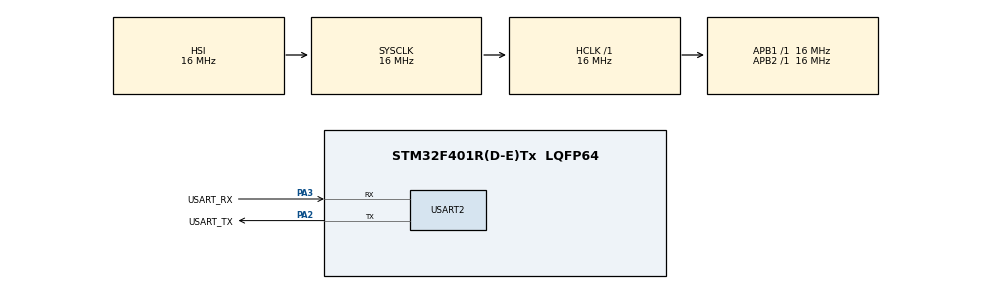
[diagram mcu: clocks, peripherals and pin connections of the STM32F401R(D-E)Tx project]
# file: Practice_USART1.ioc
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Mcu.Family=STM32F4
Mcu.Name=STM32F401R(D-E)Tx
Mcu.Package=LQFP64
NVIC.PriorityGroup=NVIC_PRIORITYGROUP_4
NVIC.USART2_IRQn=true\:1\:0\:true\:false\:true\:true\:true
PA2.GPIO_Label=USART_TX
PA2.Mode=Asynchronous
PA2.Signal=USART2_TX
PA3.GPIO_Label=USART_RX
PA3.Mode=Asynchronous
PA3.Signal=USART2_RX
ProjectManager.HeapSize=0x200
ProjectManager.StackSize=0x400
ProjectManager.TargetToolchain=TrueSTUDIO
RCC.AHBFreq_Value=16000000
RCC.APB1Freq_Value=16000000
RCC.APB2Freq_Value=16000000
RCC.CortexFreq_Value=16000000
RCC.HSE_VALUE=25000000
RCC.HSI_VALUE=16000000
RCC.LSE_VALUE=32768
RCC.SYSCLKFreq_VALUE=16000000
RCC.VCOOutputFreq_Value=192000000
USART2.VirtualMode=VM_ASYNC
board=custom

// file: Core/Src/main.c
/* USER CODE BEGIN Header */
/**
  ******************************************************************************
  * @file           : main.c
  * @brief          : Main program body
  ******************************************************************************
  * @attention
  *
  * <h2><center>&copy; Copyright (c) 2022 STMicroelectronics.
  * All rights reserved.</center></h2>
  *
  * This software component is licensed by ST under BSD 3-Clause license,
  * the "License"; You may not use this file except in compliance with the
  * License. You may obtain a copy of the License at:
  *                        opensource.org/licenses/BSD-3-Clause
  *
  ******************************************************************************
  */
/* USER CODE END Header */
#include "main.h"

/* USER CODE BEGIN Includes */
//ヘッダファイルのインクルード
#include <string.h>
/* USER CODE END Includes */

UART_HandleTypeDef huart2;

void SystemClock_Config(void);
static void MX_GPIO_Init(void);
static void MX_USART2_UART_Init(void);

/* USER CODE BEGIN 0 */
//uart_status変数の作成
__IO uint8_t uart_status;
//送受信格納用変数(8byte)
uint8_t uartbuff[8];
/* USER CODE END 0 */

int main(void)
{

  /* MCU Configuration--------------------------------------------------------*/

  /* Reset of all peripherals, Initializes the Flash interface and the Systick. */
  HAL_Init();

  /* Configure the system clock */
  SystemClock_Config();

  /* Initialize all configured peripherals */
  MX_GPIO_Init();
  MX_USART2_UART_Init();

  /* Infinite loop */
  while (1)
  {

    /* USER CODE BEGIN 3 */
	  //uart_status変数の初期化
	  uart_status = 0;
	  //送受信バッファのクリア
	  memset(uartbuff,0x00,sizeof(uartbuff));

	  //HAL_UART_Receive_ITはUART受信割込みITを開始するための、関数
	  /*第一引数：使用するUARTハンドラ
　　　 　第二引数：受信するためのバッファ
　　　　 第三引数：受信するバイト数*/
	  if(HAL_UART_Receive_IT(&huart2,uartbuff,1)== HAL_OK)
	  {
		  while(uart_status != 3)
		  {
			  switch(uart_status){
			  case 0:break; /*receive complete wait*/
			  case 1:
				  uart_status = 2;
				  /*UART送信開始用関数*/
				  /*第一引数：送信に使用するUARTハンドラ
　　　　　　　　　　　　 第二引数：送信するためのバッファ
　　　　　　　　　　　　 第三引数：送信バイト数*/
				  HAL_UART_Transmit_IT(&huart2,uartbuff,strlen((char const*)uartbuff));
				  break;
			  case 2:break;/*transmit complete wait*/
			  case 3:break;/*end*/
			  }/*end of switch*/
		  }/*end of while*/
	  }/*end of if*/
  }
  /* USER CODE END 3 */
}

void SystemClock_Config(void)
{
  RCC_OscInitTypeDef RCC_OscInitStruct = {0};
  RCC_ClkInitTypeDef RCC_ClkInitStruct = {0};

  /** Configure the main internal regulator output voltage
  */
  __HAL_RCC_PWR_CLK_ENABLE();
  __HAL_PWR_VOLTAGESCALING_CONFIG(PWR_REGULATOR_VOLTAGE_SCALE2);
  /** Initializes the RCC Oscillators according to the specified parameters
  * in the RCC_OscInitTypeDef structure.
  */
  RCC_OscInitStruct.OscillatorType = RCC_OSCILLATORTYPE_HSI;
  RCC_OscInitStruct.HSIState = RCC_HSI_ON;
  RCC_OscInitStruct.HSICalibrationValue = RCC_HSICALIBRATION_DEFAULT;
  RCC_OscInitStruct.PLL.PLLState = RCC_PLL_NONE;
  if (HAL_RCC_OscConfig(&RCC_OscInitStruct) != HAL_OK)
  {
    Error_Handler();
  }
  /** Initializes the CPU, AHB and APB buses clocks
  */
  RCC_ClkInitStruct.ClockType = RCC_CLOCKTYPE_HCLK|RCC_CLOCKTYPE_SYSCLK
                              |RCC_CLOCKTYPE_PCLK1|RCC_CLOCKTYPE_PCLK2;
  RCC_ClkInitStruct.SYSCLKSource = RCC_SYSCLKSOURCE_HSI;
  RCC_ClkInitStruct.AHBCLKDivider = RCC_SYSCLK_DIV1;
  RCC_ClkInitStruct.APB1CLKDivider = RCC_HCLK_DIV1;
  RCC_ClkInitStruct.APB2CLKDivider = RCC_HCLK_DIV1;

  if (HAL_RCC_ClockConfig(&RCC_ClkInitStruct, FLASH_LATENCY_0) != HAL_OK)
  {
    Error_Handler();
  }
}

static void MX_USART2_UART_Init(void)
{

  huart2.Instance = USART2;
  huart2.Init.BaudRate = 115200;
  huart2.Init.WordLength = UART_WORDLENGTH_8B;
  huart2.Init.StopBits = UART_STOPBITS_1;
  huart2.Init.Parity = UART_PARITY_NONE;
  huart2.Init.Mode = UART_MODE_TX_RX;
  huart2.Init.HwFlowCtl = UART_HWCONTROL_NONE;
  huart2.Init.OverSampling = UART_OVERSAMPLING_16;
  if (HAL_UART_Init(&huart2) != HAL_OK)
  {
    Error_Handler();
  }

}

static void MX_GPIO_Init(void)
{

  /* GPIO Ports Clock Enable */
  __HAL_RCC_GPIOA_CLK_ENABLE();

}

/* USER CODE BEGIN 4 */
void HAL_UART_RxCpltCallback(UART_HandleTypeDef*huart)
{
	if(&huart2 == huart)
	{
		uart_status = 1;
	}
}
//どのUARTから割り込みが入ったのかを確認
void HAL_UART_TxCpltCallback(UART_HandleTypeDef*huart)
{
	if(&huart2 == huart)
	{
		uart_status = 3;
	}
}
/* USER CODE END 4 */

void Error_Handler(void)
{
  __disable_irq();
  while (1)
  {
  }
}

/************************ (C) COPYRIGHT STMicroelectronics *****END OF FILE****/
